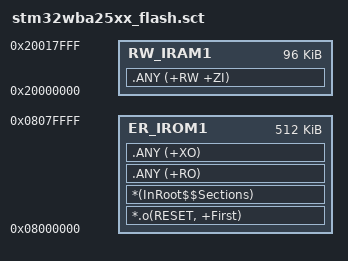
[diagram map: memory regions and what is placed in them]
; *************************************************************
; *** Scatter-Loading Description File                      ***
; *************************************************************
LR_IROM1 0x08000000 0x00080000 {
  ER_IROM1 0x08000000 0x00080000 {
    *.o(RESET, +First)
    *(InRoot$$Sections)
    .ANY (+RO)
    .ANY (+XO)
  }

  RW_IRAM1 0x20000000 0x18000 {
    .ANY (+RW +ZI)
  }
}

